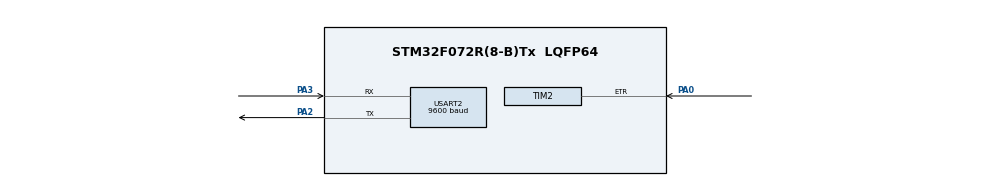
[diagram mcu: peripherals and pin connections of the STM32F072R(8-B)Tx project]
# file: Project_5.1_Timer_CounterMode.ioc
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Mcu.Family=STM32F0
Mcu.Name=STM32F072R(8-B)Tx
Mcu.Package=LQFP64
NVIC.TIM2_IRQn=true\:0\:0\:false\:false\:true\:true\:true\:true
PA0.Signal=S_TIM2_CH1_ETR
PA2.Mode=Asynchronous
PA2.Signal=USART2_TX
PA3.Mode=Asynchronous
PA3.Signal=USART2_RX
PF0-OSC_IN.Mode=HSE-External-Oscillator
PF0-OSC_IN.Signal=RCC_OSC_IN
PF1-OSC_OUT.Mode=HSE-External-Oscillator
PF1-OSC_OUT.Signal=RCC_OSC_OUT
ProjectManager.HeapSize=0x200
ProjectManager.StackSize=0x400
ProjectManager.TargetToolchain=STM32CubeIDE
SH.S_TIM2_CH1_ETR.0=TIM2_ETR,ClockSourceETR_Mode2
TIM2.AutoReloadPreload=TIM_AUTORELOAD_PRELOAD_ENABLE
TIM2.ClockFilter=15
TIM2.Period=15
USART2.BaudRate=9600
USART2.VirtualMode-Asynchronous=VM_ASYNC
board=custom

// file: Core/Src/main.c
/* USER CODE BEGIN Header */
/**
  ******************************************************************************
  * @file           : main.c
  * @brief          : Main program body
  ******************************************************************************
  * @attention
  *
  * Copyright (c) 2023 STMicroelectronics.
  * All rights reserved.
  *
  * This software is licensed under terms that can be found in the LICENSE file
  * in the root directory of this software component.
  * If no LICENSE file comes with this software, it is provided AS-IS.
  *
  ******************************************************************************
  */
/* USER CODE END Header */
#include "main.h"

TIM_HandleTypeDef htim2;

UART_HandleTypeDef huart2;

void SystemClock_Config(void);
static void MX_GPIO_Init(void);
static void MX_TIM2_Init(void);
static void MX_USART2_UART_Init(void);

/* USER CODE BEGIN 0 */
uint8_t overflow_msg[50] = "Overflow occurred - Counter reset!\n\r";

/* USER CODE END 0 */

int main(void)
{

  /* MCU Configuration--------------------------------------------------------*/

  /* Reset of all peripherals, Initializes the Flash interface and the Systick. */
  HAL_Init();

  /* USER CODE BEGIN Init */
  uint8_t msg[25] = {'\0'};
  uint16_t CounterTicks = 0;
  /* USER CODE END Init */

  /* Configure the system clock */
  SystemClock_Config();

  /* Initialize all configured peripherals */
  MX_GPIO_Init();
  MX_TIM2_Init();
  MX_USART2_UART_Init();
  /* USER CODE BEGIN 2 */
  HAL_TIM_Base_Start_IT(&htim2);
  /* USER CODE END 2 */

  /* Infinite loop */
  while (1)
  {

    /* USER CODE BEGIN 3 */

      CounterTicks = TIM2->CNT;						 				// counter value is kept in CNT register of Timer 2.
      	  	  	  	  	  	  	  	  	  	  	  	   	   	   	   //This is why we read the TIM2->CNT register.

      sprintf(msg, "Value of counter = %d\n\r", CounterTicks);	 // Print The  Counter valur Via UART2
      HAL_UART_Transmit(&huart2, msg, sizeof(msg), 100);
      HAL_Delay(100);
  }
  /* USER CODE END 3 */
}
void HAL_TIM_PeriodElapsedCallback(TIM_HandleTypeDef *htim)
{
    HAL_UART_Transmit(&huart2, overflow_msg, sizeof(overflow_msg), 100);

}

void SystemClock_Config(void)
{
  RCC_OscInitTypeDef RCC_OscInitStruct = {0};
  RCC_ClkInitTypeDef RCC_ClkInitStruct = {0};
  RCC_PeriphCLKInitTypeDef PeriphClkInit = {0};

  /** Initializes the RCC Oscillators according to the specified parameters
  * in the RCC_OscInitTypeDef structure.
  */
  RCC_OscInitStruct.OscillatorType = RCC_OSCILLATORTYPE_HSI;
  RCC_OscInitStruct.HSIState = RCC_HSI_ON;
  RCC_OscInitStruct.HSICalibrationValue = RCC_HSICALIBRATION_DEFAULT;
  RCC_OscInitStruct.PLL.PLLState = RCC_PLL_NONE;
  if (HAL_RCC_OscConfig(&RCC_OscInitStruct) != HAL_OK)
  {
    Error_Handler();
  }

  /** Initializes the CPU, AHB and APB buses clocks
  */
  RCC_ClkInitStruct.ClockType = RCC_CLOCKTYPE_HCLK|RCC_CLOCKTYPE_SYSCLK
                              |RCC_CLOCKTYPE_PCLK1;
  RCC_ClkInitStruct.SYSCLKSource = RCC_SYSCLKSOURCE_HSI;
  RCC_ClkInitStruct.AHBCLKDivider = RCC_SYSCLK_DIV1;
  RCC_ClkInitStruct.APB1CLKDivider = RCC_HCLK_DIV1;

  if (HAL_RCC_ClockConfig(&RCC_ClkInitStruct, FLASH_LATENCY_0) != HAL_OK)
  {
    Error_Handler();
  }
  PeriphClkInit.PeriphClockSelection = RCC_PERIPHCLK_USART2;
  PeriphClkInit.Usart2ClockSelection = RCC_USART2CLKSOURCE_PCLK1;
  if (HAL_RCCEx_PeriphCLKConfig(&PeriphClkInit) != HAL_OK)
  {
    Error_Handler();
  }
}

static void MX_TIM2_Init(void)
{

  TIM_ClockConfigTypeDef sClockSourceConfig = {0};
  TIM_MasterConfigTypeDef sMasterConfig = {0};

  htim2.Instance = TIM2;
  htim2.Init.Prescaler = 0;
  htim2.Init.CounterMode = TIM_COUNTERMODE_UP;
  htim2.Init.Period = 15;
  htim2.Init.ClockDivision = TIM_CLOCKDIVISION_DIV1;
  htim2.Init.AutoReloadPreload = TIM_AUTORELOAD_PRELOAD_ENABLE;
  if (HAL_TIM_Base_Init(&htim2) != HAL_OK)
  {
    Error_Handler();
  }
  sClockSourceConfig.ClockSource = TIM_CLOCKSOURCE_ETRMODE2;
  sClockSourceConfig.ClockPolarity = TIM_CLOCKPOLARITY_NONINVERTED;
  sClockSourceConfig.ClockPrescaler = TIM_CLOCKPRESCALER_DIV1;
  sClockSourceConfig.ClockFilter = 15;
  if (HAL_TIM_ConfigClockSource(&htim2, &sClockSourceConfig) != HAL_OK)
  {
    Error_Handler();
  }
  sMasterConfig.MasterOutputTrigger = TIM_TRGO_RESET;
  sMasterConfig.MasterSlaveMode = TIM_MASTERSLAVEMODE_DISABLE;
  if (HAL_TIMEx_MasterConfigSynchronization(&htim2, &sMasterConfig) != HAL_OK)
  {
    Error_Handler();
  }

}

static void MX_USART2_UART_Init(void)
{

  huart2.Instance = USART2;
  huart2.Init.BaudRate = 9600;
  huart2.Init.WordLength = UART_WORDLENGTH_8B;
  huart2.Init.StopBits = UART_STOPBITS_1;
  huart2.Init.Parity = UART_PARITY_NONE;
  huart2.Init.Mode = UART_MODE_TX_RX;
  huart2.Init.HwFlowCtl = UART_HWCONTROL_NONE;
  huart2.Init.OverSampling = UART_OVERSAMPLING_16;
  huart2.Init.OneBitSampling = UART_ONE_BIT_SAMPLE_DISABLE;
  huart2.AdvancedInit.AdvFeatureInit = UART_ADVFEATURE_NO_INIT;
  if (HAL_UART_Init(&huart2) != HAL_OK)
  {
    Error_Handler();
  }

}

static void MX_GPIO_Init(void)
{

  /* GPIO Ports Clock Enable */
  __HAL_RCC_GPIOF_CLK_ENABLE();
  __HAL_RCC_GPIOA_CLK_ENABLE();

}

void Error_Handler(void)
{
  __disable_irq();
  while (1)
  {
  }
}
